# MCF5441x register map
Vendor: NXP; File version: 1.0
Registers are 32-bit, read-write, reset 0x0 unless marked. A register's access mark holds for its fields unless they carry their own. Offsets are from the block's base; [hi:lo] are bit positions.

## DAC0
Base 0xFC098000
Same registers: DAC1 0xFC09C000
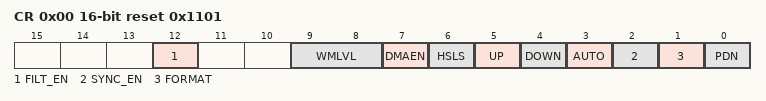
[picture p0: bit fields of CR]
0x00 CR 16-bit reset 0x1101
  [12] FILT_EN
  [9:8] WMLVL
  [7] DMAEN
    0=DISABLED; 1=ENABLED
  [6] HSLS
    0=HIGH_SPEED_MODE; 1=LOW_SPEED_MODE
  [5] UP
    0=DISABLED; 1=ENABLED
  [4] DOWN
    0=DISABLED; 1=ENABLED
  [3] AUTO
  [2] SYNC_EN
  [1] FORMAT
    0=RIGHT_JUSTIFIED; 1=LEFT_JUSTIFIED
  [0] PDN
    0=OPERATIONAL; 1=POWERED_DOWN
0x02 DATA 16-bit
0x04 STEP 16-bit
0x06 MIN 16-bit
0x08 MAX 16-bit reset 0xFFFF
0x0A SR 16-bit ro reset 0x1
0x0C FILTCNT 16-bit reset 0x1D
  [5:0] FILTCNT

## DDRMC
Base 0xFC0B8000
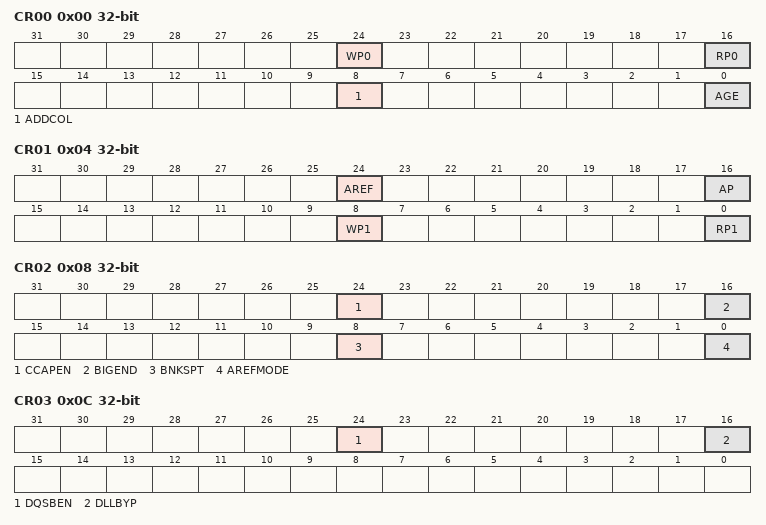
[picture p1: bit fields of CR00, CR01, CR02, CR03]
0x00 CR00
  [24] WP0
    0=HIGHEST; 1=LOWEST
  [16] RP0
    0=HIGHEST; 1=LOWEST
  [8] ADDCOL
    0=DISABLE; 1=ENABLE
  [0] AGE
    0=DISABLE; 1=ENABLE
0x04 CR01
  [24] AREF
  [16] AP
  [8] WP1
    0=HIGHEST; 1=LOWEST
  [0] RP1
    0=HIGHEST; 1=LOWEST
0x08 CR02
  [24] CCAPEN
    0=DISABLED; 1=ENABLED
  [16] BIGEND
    0=LITTLE_ENDIAN; 1=BIG_ENDIAN
  [8] BNKSPT
    0=DISABLED; 1=ENABLED
  [0] AREFMODE
0x0C CR03
  [24] DQSBEN
    0=SINGLE_ENDED; 1=DIFFERENTIAL
  [16] DLLBYP
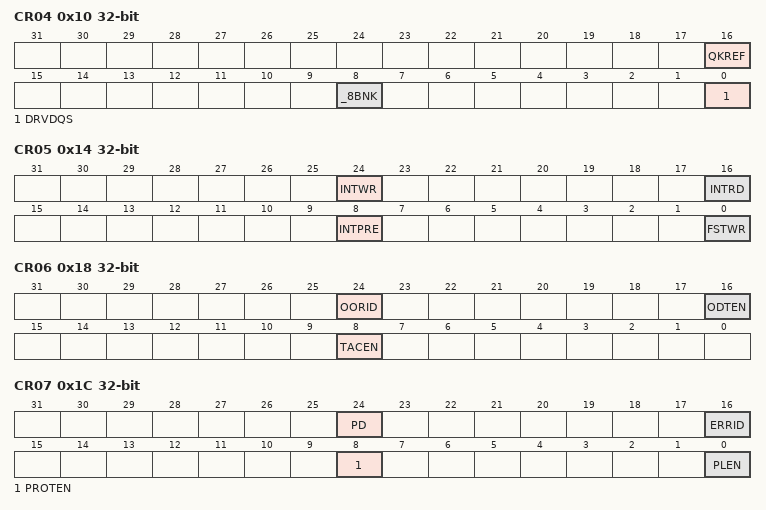
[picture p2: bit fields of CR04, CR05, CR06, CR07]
0x10 CR04
  [16] QKREF, [8] _8BNK, [0] DRVDQS
0x14 CR05
  [24] INTWR
    0=DISABLE; 1=ENABLE
  [16] INTRD
    0=DISABLE; 1=ENABLE
  [8] INTPRE
  [0] FSTWR
0x18 CR06
  [24] OORID, [16] ODTEN, [8] TACEN
0x1C CR07
  [24] PD, [16] ERRID, [8] PROTEN, [0] PLEN
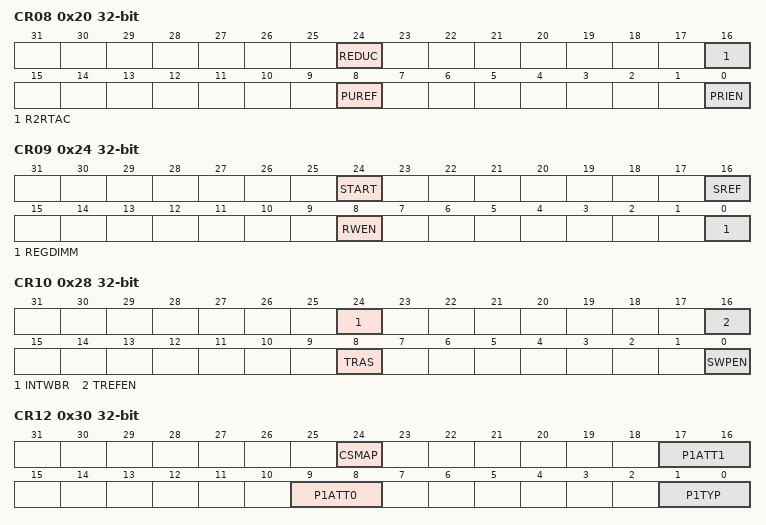
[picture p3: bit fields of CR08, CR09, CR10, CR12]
0x20 CR08
  [24] REDUC
  [16] R2RTAC
    0=DISABLED; 1=ENABLED
  [8] PUREF
    0=DISABLED; 1=ENABLED
  [0] PRIEN
    0=DISABLED; 1=ENABLED
0x24 CR09
  [24] START
  [16] SREF
  [8] RWEN
    0=DISABLED; 1=ENABLED
  [0] REGDIMM
    0=NORMAL_OPERATION; 1=ENABLE_REGISTERED_DIMM_OPERATION
0x28 CR10
  [24] INTWBR
  [16] TREFEN
    0=DISABLED; 1=ENABLED
  [8] TRAS
  [0] SWPEN
    0=DISABLED; 1=ENABLED
0x2C CR11
0x30 CR12
  [24] CSMAP
    0=DISABLED; 1=ENABLED
  [17:16] P1ATT1
    0=NO_ACCESS; 1=READ_ONLY; 2=WRITE_ONLY; 3=READ_AND_WRITE
  [9:8] P1ATT0
    0=NO_ACCESS; 1=READ_ONLY; 2=WRITE_ONLY; 3=READ_AND_WRITE
  [1:0] P1TYP
    0=ASYNCHRONOUS; 3=SYNCHRONOUS
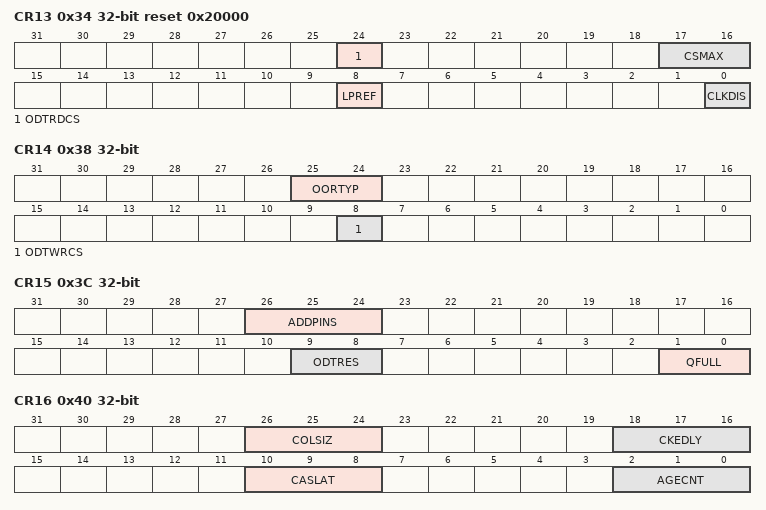
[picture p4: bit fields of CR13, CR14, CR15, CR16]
0x34 CR13 reset 0x20000
  [24] ODTRDCS
  [17:16] CSMAX
    0=ZERO; 1=ONE; 2=TWO
  [8] LPREF
    0=OCCUR; 1=DO_NOT_OCCUR
  [0] CLKDIS
    0=ENABLE_MEMORY_CLOCKS; 1=DISABLE_MEMORY_CLOCKS
0x38 CR14
  [25:24] OORTYP, [8] ODTWRCS
0x3C CR15
  [26:24] ADDPINS
  [9:8] ODTRES
    0=TERMINATION_DISABLED
  [1:0] QFULL
0x40 CR16
  [26:24] COLSIZ, [18:16] CKEDLY, [10:8] CASLAT, [2:0] AGECNT
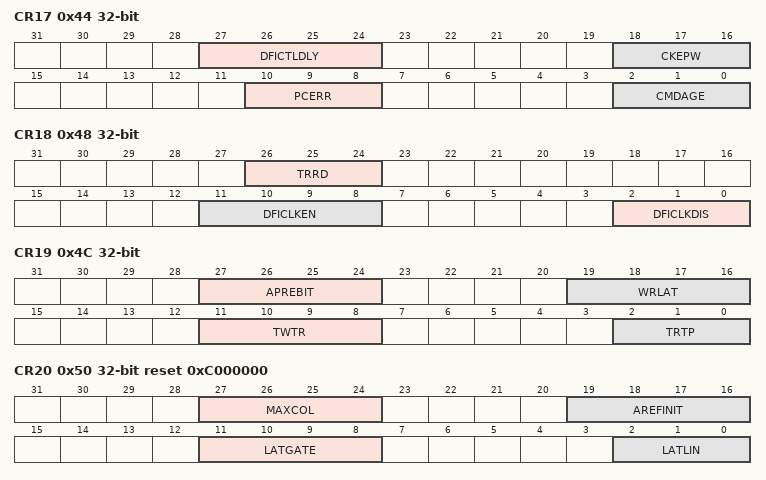
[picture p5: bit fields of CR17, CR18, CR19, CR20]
0x44 CR17
  [27:24] DFICTLDLY, [18:16] CKEPW, [10:8] PCERR, [2:0] CMDAGE
0x48 CR18
  [26:24] TRRD, [11:8] DFICLKEN, [2:0] DFICLKDIS
0x4C CR19
  [27:24] APREBIT, [19:16] WRLAT, [11:8] TWTR, [2:0] TRTP
0x50 CR20 reset 0xC000000
  [27:24] MAXCOL, [19:16] AREFINIT, [11:8] LATGATE, [2:0] LATLIN
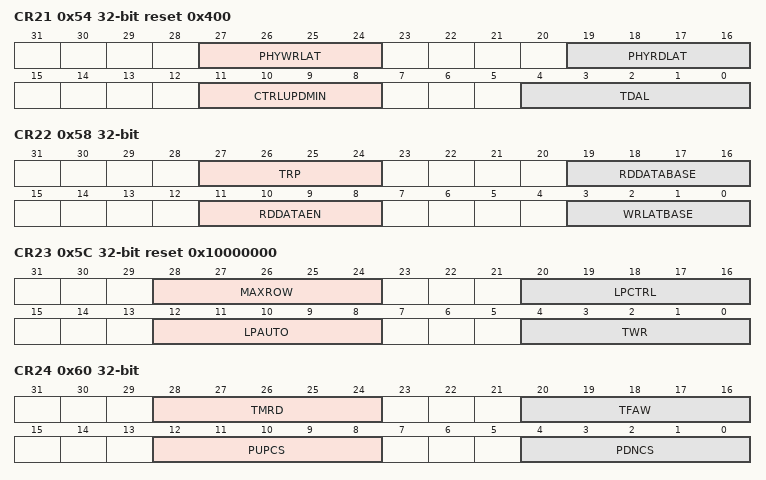
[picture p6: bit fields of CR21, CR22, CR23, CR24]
0x54 CR21 reset 0x400
  [27:24] PHYWRLAT, [19:16] PHYRDLAT, [11:8] CTRLUPDMIN, [4:0] TDAL
0x58 CR22
  [27:24] TRP, [19:16] RDDATABASE, [11:8] RDDATAEN, [3:0] WRLATBASE
0x5C CR23 reset 0x10000000
  [28:24] MAXROW, [20:16] LPCTRL, [12:8] LPAUTO, [4:0] TWR
0x60 CR24
  [28:24] TMRD, [20:16] TFAW, [12:8] PUPCS, [4:0] PDNCS
0x64 CR25
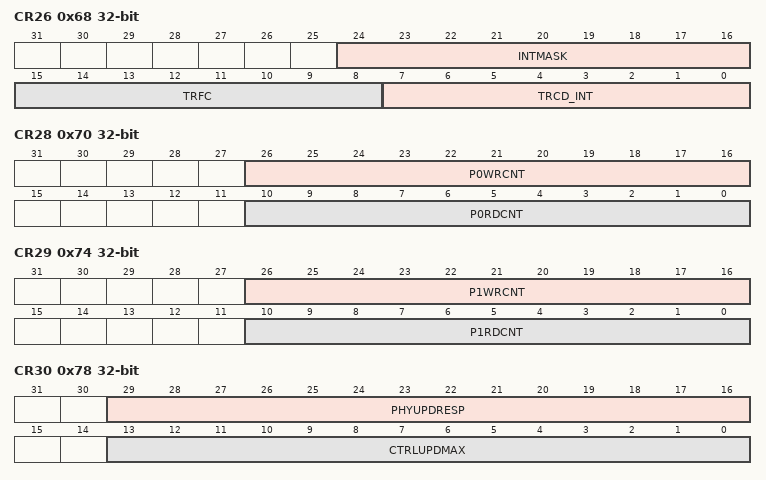
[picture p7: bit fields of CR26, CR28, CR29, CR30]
0x68 CR26
  [24:16] INTMASK, [15:8] TRFC, [7:0] TRCD_INT
0x6C CR27 ro
0x70 CR28
  [26:16] P0WRCNT, [10:0] P0RDCNT
0x74 CR29
  [26:16] P1WRCNT, [10:0] P1RDCNT
0x78 CR30 ro
  [29:16] PHYUPDRESP, [13:0] CTRLUPDMAX
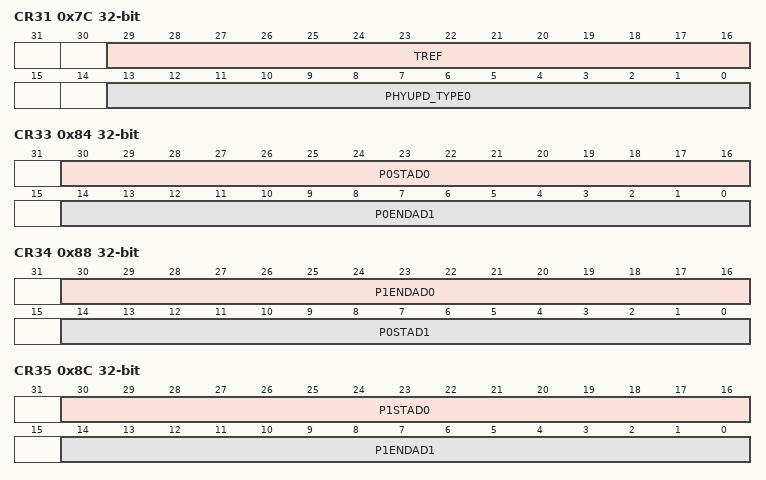
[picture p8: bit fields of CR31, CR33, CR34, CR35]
0x7C CR31
  [29:16] TREF, [13:0] PHYUPD_TYPE0
0x80 CR32
  [30:16] P0ENDAD0
0x84 CR33
  [30:16] P0STAD0, [14:0] P0ENDAD1
0x88 CR34
  [30:16] P1ENDAD0, [14:0] P0STAD1
0x8C CR35
  [30:16] P1STAD0, [14:0] P1ENDAD1
0x90 CR36
  [14:0] P1STAD1
0x94 CR37
  [15:0] EMRS2D
0x98 CR38
  [31:16] LPEXTCNT
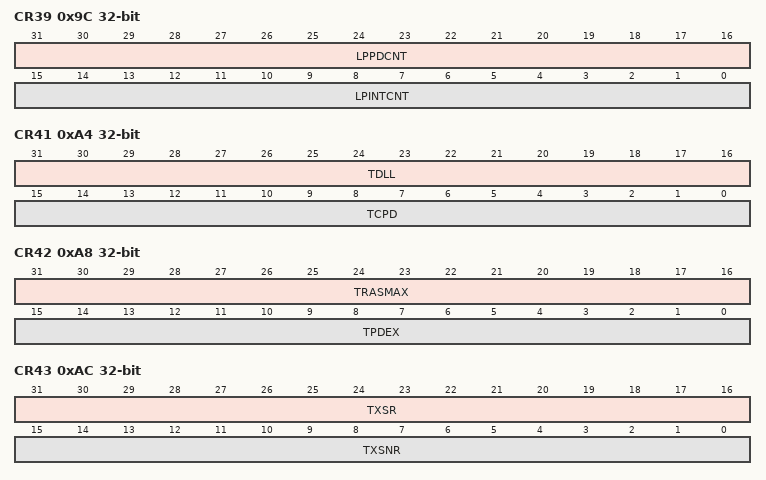
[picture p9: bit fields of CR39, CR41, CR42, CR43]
0x9C CR39
  [31:16] LPPDCNT, [15:0] LPINTCNT
0xA0 CR40
  [31:16] LPSREFCNT
0xA4 CR41
  [31:16] TDLL, [15:0] TCPD
0xA8 CR42
  [31:16] TRASMAX, [15:0] TPDEX
0xAC CR43
  [31:16] TXSR, [15:0] TXSNR
0xB0 CR44 ro reset 0x2040
  [15:0] VERSION
0xB4 CR45
  [23:0] TINIT
0xD4 CR53 ro
0xDC CR55 ro
  [31:0] OORAD
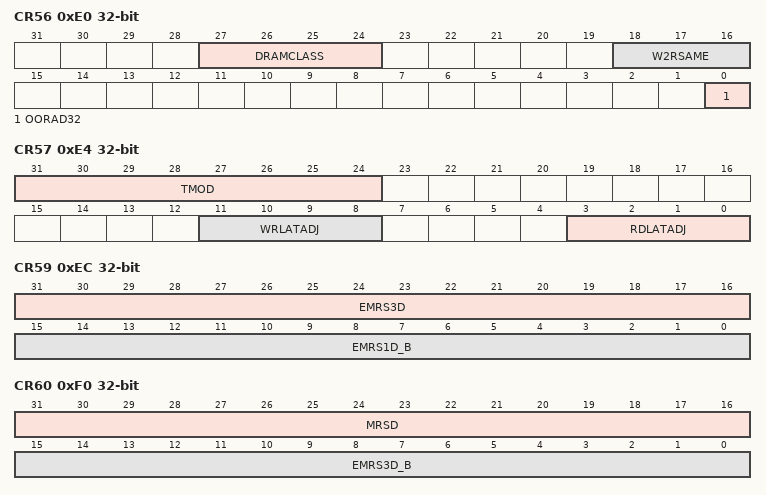
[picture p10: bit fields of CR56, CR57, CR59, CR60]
0xE0 CR56
  [27:24] DRAMCLASS
    4=DDR2
  [18:16] W2RSAME
  [0] OORAD32
0xE4 CR57
  [31:24] TMOD, [11:8] WRLATADJ, [3:0] RDLATADJ
0xE8 CR58
  [31:16] EMRS1D
0xEC CR59
  [31:16] EMRS3D, [15:0] EMRS1D_B
0xF0 CR60
  [31:16] MRSD, [15:0] EMRS3D_B
0x180 RCR
  [30] RST
    0=NO_SOFTWARE_RESET; 1=FORCE_SOFTWARE_RESET
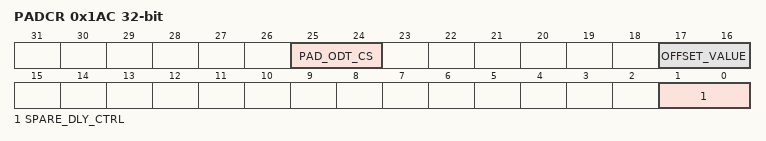
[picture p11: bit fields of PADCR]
0x1AC PADCR
  [25:24] PAD_ODT_CS, [17:16] OFFSET_VALUE, [1:0] SPARE_DLY_CTRL
